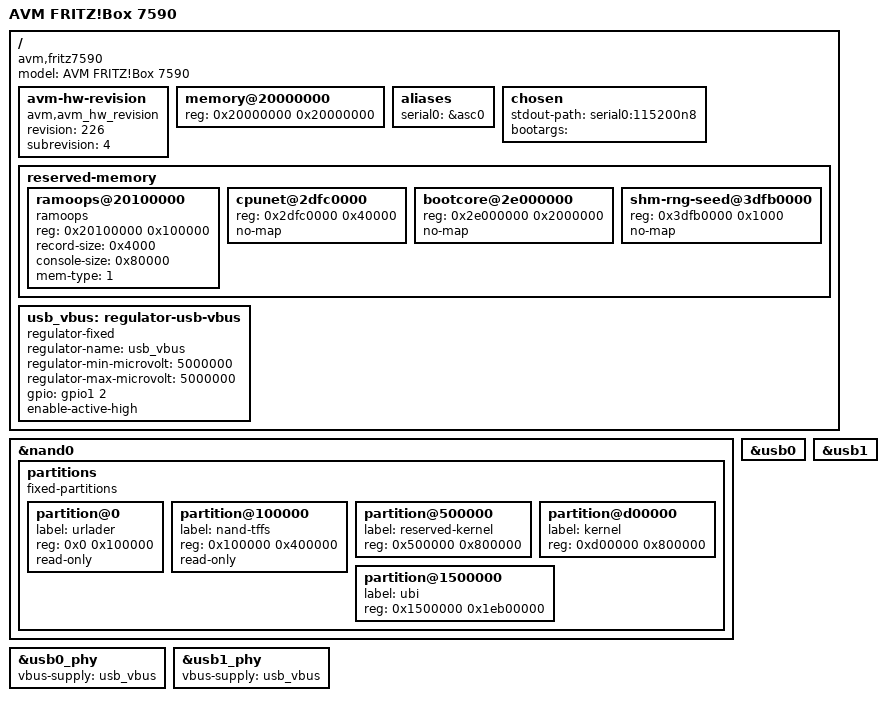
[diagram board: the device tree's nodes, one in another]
// SPDX-License-Identifier: GPL-2.0-only
// Copyright (C) 2026 Grische <github@grische.xyz>
/*
 * AVM FRITZ!Box 7590 (HW226), GRX550. Board-specific data only; the SoC is
 * described in xrx500.dtsi, the board family in seale_avm.dtsi and the die
 * variant in seale_avm_grx550.dtsi.
 */
/dts-v1/;

#include <dt-bindings/gpio/gpio.h>

#include "seale_avm.dtsi"

/ {
	model = "AVM FRITZ!Box 7590";
	compatible = "avm,fritz7590", "intel,xrx500";

	/*
	 * The boot loader carries a table of device-tree blobs keyed by
	 * hardware sub-revision. Declaring the tag is cosmetic here — the
	 * loader passes this kernel no device tree and the appended blob is
	 * parsed unconditionally — but it stops the loader reporting an
	 * unmatched sub-revision.
	 */
	avm-hw-revision {
		compatible = "avm,avm_hw_revision";
		revision = "226";
		subrevision = "4";
	};

	/*
	 * The board's full 512 MiB, at PHYS_OFFSET 0x20000000.
	 *
	 * ## THIS DTB IS SINGLE-KERNEL-ONLY.                      ##
	 * ## Booting it from a dual-kernel container corrupts or  ##
	 * ## hangs, and it does so silently at first.             ##
	 *
	 * The coupling is exact and it is not a style preference. The
	 * bootcore's protect_unattached() takes the ram-size = <256> its own
	 * device tree declares and programs a PM_DDR_GROUP_NONE deny-all
	 * fabric region over its 32 MiB window at [0x2e000000, 0x2fffffff]
	 * and over everything above that size, [0x30000000, 0x9fffffff].
	 *
	 * The upper half of this board's populated DRAM -- precisely the half
	 * this memory node now declares -- is then denied to every initiator.
	 * The failure is a fault or hang on first touch of anything above
	 * 0x30000000, and it is not the KSEG1-aperture class and not helped
	 * by staying under that bound.
	 *
	 * A single-kernel image starts no bootcore, so the protection pass
	 * never runs and this node is safe.
	 *
	 * Two bounds that did NOT move and still apply at 512 MiB:
	 *
	 * The uncached KSEG1 alias of DRAM ends at PHYS_OFFSET + 0x12310000 =
	 * 0x32310000 (~291 MiB), measured. Cached RAM is fine across the
	 * whole node -- under EVA's SegCtl, KSEG0 maps 0x80000000 to
	 * 0x20000000 and covers all 512 MiB -- but general
	 * dma_alloc_coherent() consumers must stay below 0x32310000. hdma is
	 * already re-bound to that aperture; a new uncached consumer is what
	 * would break here first, not the node width. The CBM pools at
	 * 0x23800000..0x25200000 that seale_avm.dtsi reserves cannot move,
	 * only be extended past.
	 */
	memory@20000000 {
		device_type = "memory";
		reg = <0x20000000 0x20000000>;
	};

	aliases {
		serial0 = &asc0;
	};

	chosen {
		stdout-path = "serial0:115200n8";
		/*
		 * Unused while MIPS_CMDLINE_BUILTIN_EXTEND is selected;
		 * present so a board that needs its own arguments has
		 * somewhere to put them.
		 */
		bootargs = "";
	};

	/*
	 * Every region below must stay under PHYS_OFFSET + SZ_256M; the
	 * uncached alias above that address reaches registers, not DRAM.
	 */
	reserved-memory {
		#address-cells = <1>;
		#size-cells = <1>;
		ranges;

		/*
		 * Crash persistence, at the address the vendor's own device
		 * tree uses for it (its node is named ramoops@20500000 while
		 * its reg says 0x20100000). 1 MiB of the 4 MiB region below
		 * _text. The zone sizes fill reg exactly; fs/pstore/ram.c
		 * fails the whole probe if they overflow it.
		 */
		ramoops@20100000 {
			compatible = "ramoops";
			reg = <0x20100000 0x100000>;
			record-size = <0x4000>;
			console-size = <0x80000>;
			mem-type = <1>;
		};

		/*
		 * Owned by the second CPU's boot loader (the vendor ships its
		 * own device tree for that core); no-map so this kernel never
		 * maps another CPU's memory.
		 */
		cpunet@2dfc0000 {
			reg = <0x2dfc0000 0x40000>;
			no-map;
		};

		bootcore@2e000000 {
			reg = <0x2e000000 0x2000000>;
			no-map;
		};

		/*
		 * Fixed-address seed buffer shared with the second CPU;
		 * reserved no-map so nothing here maps or reads it.
		 */
		shm-rng-seed@3dfb0000 {
			reg = <0x3dfb0000 0x1000>;
			no-map;
		};
	};

	/*
	 * Port power, for both USB host controllers at once. The FRITZ!Box 7560 has
	 * one port and one enable line; this board has two ports and still
	 * one enable line. AVM declares a single gpio_avm_usb_power_enable
	 * on gpio1 2, active high, with no per-controller variant (AVM 4.9
	 * arch/mips/boot/dts/lantiq/avm/grx550_common.dtsi). That is gpio
	 * bank 1 line 2, i.e. pad 34, and nothing else on this board claims
	 * it.
	 *
	 * Both PHYs take it as their vbus-supply, which is legal and
	 * refcounted: the PHY driver asks with regulator_get_optional(), and
	 * only an exclusive get would turn a second consumer away. Whichever
	 * PHY powers on first raises the line and it drops again when the
	 * last one powers off.
	 *
	 * The vendor mechanism, and the reason for not reproducing it, are
	 * the FRITZ!Box 7560's: see the comment on that board's usb_vbus.
	 *
	 * No pinmux, for the same reason as there: the pad comes up as a
	 * GPIO, which is what the regulator needs.
	 */
	usb_vbus: regulator-usb-vbus {
		compatible = "regulator-fixed";
		regulator-name = "usb_vbus";
		regulator-min-microvolt = <5000000>;
		regulator-max-microvolt = <5000000>;
		gpio = <&gpio1 2 GPIO_ACTIVE_HIGH>;
		enable-active-high;
	};
};

/*
 * Toshiba BENAND, 512 MiB with a 4 KiB page; the geometry is self-identified.
 * The partition map is the one the vendor boot loader installs, so a vendor
 * recovery can hand the kernel back to the original firmware without
 * remapping flash.
 */
&nand0 {
	partitions {
		compatible = "fixed-partitions";
		#address-cells = <1>;
		#size-cells = <1>;

		/*
		 * First-stage boot loader, and the only copy of the Wi-Fi
		 * calibration data. Read-only: overwriting it bricks the
		 * device past the point of recovery without an external
		 * programmer.
		 */
		partition@0 {
			label = "urlader";
			reg = <0x0 0x100000>;
			read-only;
		};

		/*
		 * AVM TFFS environment: the only copy of this unit's
		 * identity (MAC addresses, serial number). Never
		 * written from Linux, and erasing it cannot be undone.
		 */
		partition@100000 {
			label = "nand-tffs";
			reg = <0x100000 0x400000>;
			read-only;
		};

		/* Inactive kernel slot 0. Written by sysupgrade. */
		partition@500000 {
			label = "reserved-kernel";
			reg = <0x500000 0x800000>;
		};

		/* Active kernel slot 1 -- the one EVA boots on this unit. */
		partition@d00000 {
			label = "kernel";
			reg = <0xd00000 0x800000>;
		};

		/* UBI: rootfs and rootfs_data. Ends at the 512 MiB mark. */
		partition@1500000 {
			label = "ubi";
			reg = <0x1500000 0x1eb00000>;
		};
	};
};

/*
 * Both USB host controllers. The vendor's HW226 chain carries no status
 * override on either of them, where the FRITZ!Box 7560's grx350_common.dtsi disables
 * usb0. How many jacks that reaches, and which controller sits behind each
 * one, is a board-layout fact the vendor sources do not state.
 */
&usb0_phy {
	status = "okay";
	vbus-supply = <&usb_vbus>;
};

&usb0 {
	status = "okay";
};

&usb1_phy {
	status = "okay";
	vbus-supply = <&usb_vbus>;
};

&usb1 {
	status = "okay";
};
